# AE302F80F55D5LE_CM55_HE_View register map
Vendor: Alif Semiconductor; Series: E3; File version: 1.0
CPU: CM55 r1p0, selectable endian, MPU, FPU, double-precision FPU, DSP, VTOR, 8 interrupt priority bits, 1 SAU regions
Registers are 32-bit, read-write, reset 0x0 unless marked. A register's access mark holds for its fields unless they carry their own. Offsets are from the block's base; [hi:lo] are bit positions; {n}, {i} and the like mark numbered series; 'fields as' and 'values as' point back to an identical list.

## LPI2S
Base 0x43001000
Same registers: I2S0 0x49014000, I2S1 0x49015000, I2S2 0x49016000, I2S3 0x49017000
0x00 I2S_IER — I2S Enable Register
  [0] IEN — I2S Enable. This bit enables or disables the I2S module. Disabling this bit (I2S_IER[IEN] = 0x0) overrides any other block or channel enables, and flushes all FIFOs. For more information about how this bit affects the other I2S blocks, refer to Section I2S Enable.
    0=I2S disabled; 1=I2S enabled
0x04 I2S_IRER — I2S Receiver Block Enable Register
  [0] RXEN — Receiver Block Enable. This bit enables or disables the Receiver block. Disabling this bit (I2S_IRER[RXEN] = 0x0) overrides the receive channel enables. For more information about the Receiver block, refer to Section I2S as a Receiver.
    0=Receiver disabled; 1=Receiver enabled
0x08 I2S_ITER — I2S Transmitter Block Enable Register
  [0] TXEN — Transmitter Block Enable. This bit enables or disables the Transmitter block. A disable on this bit (I2S_ITER[TXEN] = 0x0) overrides the transmit channel enables. For more information about the Transmitter block, refer to Section I2S as a Transmitter.
    0=Transmitter disabled; 1=Transmitter enabled
0x0C I2S_CER — Clock Enable Register
  [0] CLKEN — Clock Generation Enable or Disable. This bit enables or disables the clock generation signals when the I2S module is a master: SCLK_EN, WS_OUT, and SCLK_GATE. For more information about clock generation, refer to Section I2S Clocks.
    0=Clock generation disabled; 1=Clock generation enabled
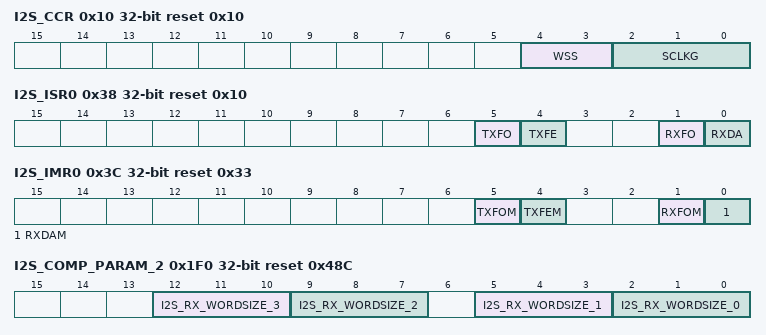
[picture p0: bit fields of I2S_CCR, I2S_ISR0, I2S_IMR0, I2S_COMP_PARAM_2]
0x10 I2S_CCR reset 0x10 — Clock Configuration Register
  [4:3] WSS — This bit field is used to program the number of SCLK cycles for which the word select line (WS_OUT) stays in the left or right sample mode. The I2S Clock Generation block must be disabled (I2S_CER[CLKEN] = 0x0) prior to any changes in this value.
    0=16 SCLK cycles; 1=24 SCLK cycles; 2=32 SCLK cycles
  [2:0] SCLKG — This bit field is used to program the gating of SCLK. The programmed gating value must be less than or equal to the largest configured (programmed) audio resolution to prevent the truncating of RX/TX data. The I2S Clock Generation block must be disabled (I2S_CER[CLKEN] = 0x0) before making any changes in this value.
    0=Clock gating is disabled; 1=Gating after 12 SCLK cycles; 2=Gating after 16 SCLK cycles; 3=Gating after 20 SCLK cycles; 4=Gating after 24 SCLK cycles
0x14 I2S_RXFFR — Receiver Block FIFO Reset Register
  [0] RXFFR wo — Receiver FIFO Reset. Writing a 0x1 to this bit flushes all the RX FIFOs (this is a self clearing bit). The Receiver block must be disabled before writing to this bit.
    0=Does not flush the RX FIFO; 1=Flushes the RX FIFO
0x18 I2S_TXFFR — Transmitter Block FIFO Reset Register
  [0] TXFFR wo — Transmitter FIFO Reset. Writing a 0x1 to this bit flushes all the TX FIFOs (this is a self clearing bit). The Transmitter block must be disabled prior to writing this bit.
    0=Does not flush the TX FIFO; 1=Flushes the TX FIFO
0x20 I2S_LRBR0 ro — Left Receive Buffer Register 0
  [31:0] LRBRX — The left stereo data received serially from the receive channel input (SDI). If the RX FIFO is full and the two-stage read operation (for instance, a read from the I2S_LRBR0[LRBRX] bit field followed by a read from the I2S_RRBR0[RRBRX] bit field) is not performed before the start of the next stereo pair, then the new data is lost and an overrun interrupt occurs (data already in the RX FIFO is preserved). Note: Before reading this register again, the right stereo data must be read from the I2S_RRBR0[RRBRX] bit field or the status (interrupts) will not be valid.
0x20 I2S_LTHR0 wo (alternate view of I2S_LRBR0) — Left Transmit Holding Register 0
  [31:0] LTHRX — The left stereo data to be transmitted serially through the transmit channel output (SDO) is written through this bit field. Writing is a two-stage process: 1. A write to this bit field passes the left stereo sample to the transmitter. 2. This must be followed by writing the right stereo sample to the I2S_RTHR0[RTHRX] bit field. Note: Data must only be written to the FIFO when it is not full. Any attempt to write to a full FIFO results in that data being lost and an overrun interrupt being generated.
0x24 I2S_RRBR0 ro — Right Transmit Holding Register 0
  [31:0] RRBRX — The right stereo data received serially from the receive channel input (SDI) is read through this bit field. If the RX FIFO is full and the two-stage read operation (for instance, read from the I2S_LRBR0[LRBRX] bit field followed by a read from the I2S_RRBR0[RRBRX] bit field) is not performed before the start of the next stereo pair, then the new data is lost and an overrun interrupt occurs (data already in the RX FIFO is preserved). Note: Prior to reading this bit field, the left stereo data must be read from the I2S_LRBR0[LRBRX] bit field, or the status (interrupts) will not be valid.
0x24 I2S_RTHR0 wo (alternate view of I2S_RRBR0) — Specifies the Right Transmit Holding Register
  [31:0] RTHRX — The right stereo data to be transmitted serially through the transmit channel output (SDO) is written through this bit field. Writing is a two-stage process: 1. A left stereo sample must be written to the I2S_LTHR0[LTHRX] bit field. 2. A write to this bit field passes the right stereo sample to the transmitter. Note: Data should only be written to the FIFO when it is not full. Any attempt to write to a full FIFO results in that data being lost and an overrun interrupt being generated.
0x28 I2S_RER0 reset 0x1 — Receive Enable Register 0
  [0] RXCHENX — Receive Channel Enable. This bit enables or disables the receive channel. On enable, the channel begins receiving on the next left stereo cycle. A global disable of the I2S module (I2S_IER[IEN] = 0x0) or the Receiver block (I2S_IRER[RXEN] = 0x0) overrides this value.
    0=Receive channel disable; 1=Receive channel enable
0x2C I2S_TER0 reset 0x1 — Transmit Enable Register 0
  [0] TXCHENX — Transmit Channel Enable. This bit enables or disables the transmit channel. On enable, the channel begins transmitting on the next left stereo cycle. A global disable of the I2S module (I2S_IER[IEN] = 0x0) or Transmitter block (I2S_ITER[TXEN] = 0x0) overrides this value.
    0=Transmit channel disable; 1=Transmit channel enable
0x30 I2S_RCR0 reset 0x5 — Receive Configuration Register 0
  [2:0] WLEN — This bit field is used to program the desired data resolution of the receiver and enables the LSB of the incoming left (or right) word to be placed in the LSB of the I2S_LRBR0[LRBRX] (or I2S_RRBR0[RRBRX]) bit field. Programmed data resolution must be less than or equal to the I2S_COMP_PARAM_2[I2S_RX_WORDSIZE_x] bit field value, where x = 0 to 3. If the selected resolution is greater than the I2S_COMP_PARAM_2[I2S_RX_WORDSIZE_x] bit field value, the receive channel defaults back to the to the maximum audio data resolution supported. The channel must be disabled prior to any changes in this value (I2S_RER0[RXCHENX] = 0x0).
    0=Ignore the word length; 1=12-bit data resolution of the receiver; 2=16-bit data resolution of the receiver; 3=20-bit data resolution of the receiver; 4=24-bit data resolution of the receiver; 5=32-bit data resolution of the receiver
0x34 I2S_TCR0 reset 0x5 — Transmit Configuration Register 0
  [2:0] WLEN — This bit field is used to program the desired data resolution of the transmitter and ensures the MSB of the data is transmitted first. Programmed resolution must be less than or equal to the I2S_COMP_PARAM_1[I2S_TX_WORDSIZE_x] bit field value, where x = 0 to 3. If the selected resolution is greater than the I2S_COMP_PARAM_1[I2S_TX_WORDSIZE_x] bit field value, the transmit channel defaults back to the to the maximum audio data resolution supported. The channel must be disabled prior to any changes in this value (I2S_TER0[TXCHENX] = 0x0).
    0=Ignore the word length; 1=12-bit data resolution of the transmitter; 2=16-bit data resolution of the transmitter; 3=20-bit data resolution of the transmitter; 4=24-bit data resolution of the transmitter; 5=32-bit data resolution of the transmitter
0x38 I2S_ISR0 ro reset 0x10 — Interrupt Status Register 0
  [5] TXFO — Status of Data Overrun Interrupt for the TX Channel. This bit specifies whether the TX FIFO write is valid or an overrun (attempt to write to full TX FIFO).
    0=TX FIFO write valid; 1=TX FIFO write overrun
  [4] TXFE — Status of Transmit Empty Trigger Interrupt. This bit specifies whether the TX FIFO trigger level has reached or not (TX FIFO is empty).
    0=TX FIFO trigger level is reached; 1=TX FIFO trigger level is not reached
  [1] RXFO — Status of Data Overrun Interrupt for the RX Channel. Incoming data lost due to a full RX FIFO.
    0=RX FIFO write valid; 1=RX FIFO write overrun
  [0] RXDA — Status of Receive Data Available Interrupt. This bit denotes the status of the RX FIFO trigger level.
    0=RX FIFO trigger level is not reached; 1=RX FIFO trigger level is reached
0x3C I2S_IMR0 reset 0x33 — Interrupt Mask Register 0
  [5] TXFOM — Mask TX FIFO Overrun Interrupt. This bit masks or unmasks a TX FIFO overrun interrupt.
    1=Masks TX FIFO Overrun interrupt; 0=Unmasks TX FIFO Overrun interrupt
  [4] TXFEM — Mask TX FIFO Empty Interrupt. This bit masks or unmasks a TX FIFO Empty interrupt.
    1=Masks TX FIFO Empty interrupt; 0=Unmasks TX FIFO Empty Interrupt
  [1] RXFOM — Mask RX FIFO Overrun Interrupt. This bit masks or unmasks an RX FIFO Overrun interrupt.
    1=Masks RX FIFO Overrun interrupt; 0=Unmasks RX FIFO Overrun interrupt
  [0] RXDAM — Mask RX FIFO Data Available Interrupt. This bit masks or unmasks an RX FIFO Data Available interrupt.
    1=Masks RX FIFO data available interrupt; 0=Unmasks RX FIFO data available interrupt
0x40 I2S_ROR0 ro — Receive Overrun Register 0
  [0] RXCHO — Read this bit to clear the RX FIFO Data Overrun interrupt.
    0=RX FIFO write valid; 1=RX FIFO write overrun
0x44 I2S_TOR0 ro — Transmit Overrun Register 0
  [0] TXCHO — Read this bit to clear the TX FIFO Data Overrun interrupt.
    0=TX FIFO write valid; 1=TX FIFO write overrun
0x48 I2S_RFCR0 reset 0x3 — Receive FIFO Configuration Register 0
  [3:0] RXCHDT — This bit field programs the trigger level in the RX FIFO at which the Received Data Available interrupt and DMA request is generated (Trigger Level = Programmed Value + 1). Valid values of the I2S_RFCR0[RXCHDT] bit field: 0 to RX FIFO depth - 1. If an illegal value is programmed, this bit field saturates to RX FIFO depth - 1. For more information about FIFO depth, refer to Section I2S Overview. The channel must be disabled prior to any changes in this value (that is, I2S_RER0[RXCHENX] = 0x0).
    {v}=Interrupt trigger and DMA request asserted when FIFO level is {v+1} (v=0..15)
0x4C I2S_TFCR0 reset 0x3 — Transmit FIFO Configuration Register 0
  [3:0] TXCHET — This bit field programs the trigger level in the TX FIFO at which the Empty Threshold Reached interrupt and DMA request is generated (Trigger Level = TXCHET). Valid values of the I2S_TFCR0[TXCHET] bit field: 0 to TX FIFO depth - 1. If an illegal value is programmed, this bit field saturates to TX FIFO depth - 1. The channel must be disabled prior to any changes in this value (that is, I2S_TER0[TXCHENX] = 0x0).
    values as I2S_RFCR0.RXCHDT
0x50 I2S_RFF0 — Receive FIFO Flush Register 0
  [0] RXCHFR wo — Receive Channel FIFO Reset. Writing a 0x1 to this bit flushes the channel RX FIFO (this is a self clearing bit). The RX channel or block must be disabled prior to writing to this bit.
    0=Does not flush the channel RX FIFO; 1=Flushes the channel RX FIFO
0x54 I2S_TFF0 — Transmit FIFO Flush Register 0
  [0] TXCHFR wo — Transmit Channel FIFO Reset. Writing a 0x1 to this bit flushes the channel TX FIFO (this is a self clearing bit). The TX channel or block must be disabled prior to writing to this bit.
    0=Do not flushes the channel TX FIFO; 1=Flushes the channel TX FIFO
0x1C0 I2S_RXDMA ro — Receiver Block DMA Register
  [31:0] RXDMA — Receiver Block DMA. These bits are used to cycle repeatedly through the enabled receive channels (from lowest numbered to highest), reading stereo data pairs. For more information about the supported receive channels, refer to Section I2S Overview.
0x1C8 I2S_TXDMA wo — Transmitter Block DMA Register
  [31:0] TXDMA — Transmitter Block DMA. These bits can be used to cycle repeatedly through the enabled transmit channels (from lowest numbered to highest) to allow writing of stereo data pairs. For more information about the supported transmit channels, refer to Section I2S Overview.
0x1F0 I2S_COMP_PARAM_2 ro reset 0x48C — Module Configuration Register 2
  [12:10] I2S_RX_WORDSIZE_3 — These bits specify the RX resolution for WORDSIZE_3.
    1=16-bit Resolution
  [9:7] I2S_RX_WORDSIZE_2 — These bits specify the RX resolution for WORDSIZE_2.
    1=16-bit Resolution
  [5:3] I2S_RX_WORDSIZE_1 — These bits specify the RX resolution for WORDSIZE_1.
    1=16-bit Resolution
  [2:0] I2S_RX_WORDSIZE_0 — These bits specify the RX resolution for WORDSIZE_0.
    4=32-bit Resolution
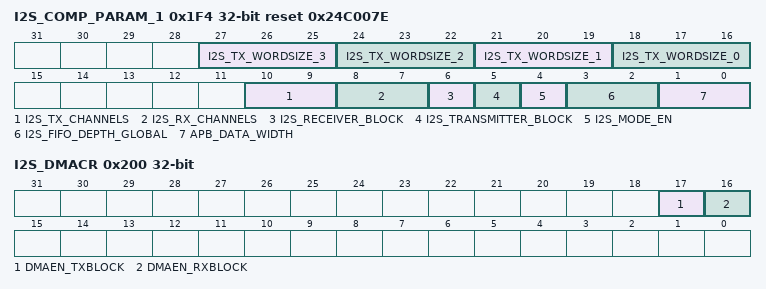
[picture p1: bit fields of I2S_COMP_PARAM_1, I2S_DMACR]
0x1F4 I2S_COMP_PARAM_1 ro reset 0x24C007E — Module Configuration Register 1
  [27:25] I2S_TX_WORDSIZE_3 — These bits specify the TX resolution for WORDSIZE_3.
    1=16-bit Resolution
  [24:22] I2S_TX_WORDSIZE_2 — These bits specify the TX resolution for WORDSIZE_2.
    1=16-bit Resolution
  [21:19] I2S_TX_WORDSIZE_1 — These bits specify the TX resolution for WORDSIZE_1.
    1=16-bit Resolution
  [18:16] I2S_TX_WORDSIZE_0 — These bits specify the TX resolution for WORDSIZE_0.
    4=32-bit Resolution
  [10:9] I2S_TX_CHANNELS — These bits specify the number of TX channels.
    0=1 x Transmit channel
  [8:7] I2S_RX_CHANNELS — These bits specify the number of RX channels.
    0=1 x Receive channel
  [6] I2S_RECEIVER_BLOCK — This bit specifies whether the receiver block is enabled or not.
    1=Receiver block is enabled
  [5] I2S_TRANSMITTER_BLOCK — This bit specifies whether the transmitter block is enabled or not.
    1=Transmitter block is enabled
  [4] I2S_MODE_EN — This bit specifies whether the Master mode is enabled or not.
    1=Master mode is enabled
  [3:2] I2S_FIFO_DEPTH_GLOBAL — These bits specify the FIFO depth for TX and RX channels.
    3=FIFO depth is equals to 16 for TX and RX channels
  [1:0] APB_DATA_WIDTH — These bits specify the APB data width.
    2=APB data width of 32 bits
0x1F8 I2S_COMP_VERSION ro reset 0x3131312A — Component Parameter Register
  [31:0] I2S_COMP_VERSION — Module component version
0x1FC I2S_COMP_TYPE ro reset 0x445701A0 — Component Type Register
  [31:0] I2S_COMP_TYPE — Component type
0x200 I2S_DMACR — DMA Control Register
  [17] DMAEN_TXBLOCK — DMA Enable for the Transmit Block. This bit enables or disables the DMA handshake logic for the transmitter block.
    0=DMA disabled for the transmit block; 1=DMA enabled for the transmit block
  [16] DMAEN_RXBLOCK — DMA Enable for the Receive Block. This bit enables or disables the DMA handshake logic for the receiver block.
    0=DMA disabled for the receiver block; 1=DMA enabled for the receiver block
